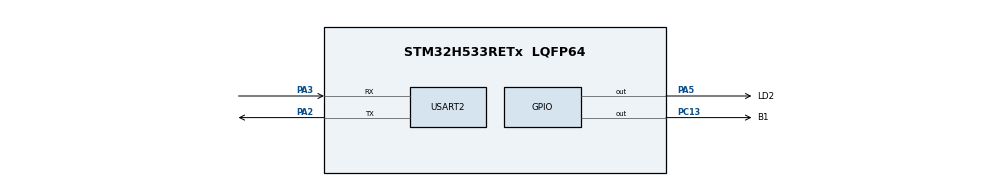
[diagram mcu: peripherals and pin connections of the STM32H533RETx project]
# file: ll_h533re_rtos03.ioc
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BOOTPATH.BootPathName=LEGACY
BOOTPATH.UserSelectedBootPath=LEGACY
CORTEX_M33_NS.userName=CORTEX_M33
Mcu.Family=STM32H5
Mcu.Name=STM32H533RETx
Mcu.Package=LQFP64
NVIC.PriorityGroup=NVIC_PRIORITYGROUP_4
PA2.Mode=Asynchronous
PA2.Signal=USART2_TX
PA3.Mode=Asynchronous
PA3.Signal=USART2_RX
PA5.GPIO_Label=LD2
PA5.Signal=GPIO_Output
PC13.GPIO_Label=B1
PC13.Signal=GPIO_Output
ProjectManager.HeapSize=0x200
ProjectManager.StackSize=0x400
ProjectManager.TargetToolchain=STM32CubeIDE
RCC.ADCFreq_Value=250000000
RCC.AHBFreq_Value=250000000
RCC.APB1Freq_Value=250000000
RCC.APB1TimFreq_Value=250000000
RCC.APB2Freq_Value=250000000
RCC.APB2TimFreq_Value=250000000
RCC.APB3Freq_Value=250000000
RCC.CSI_VALUE=4000000
RCC.CortexFreq_Value=250000000
RCC.EPOD_VALUE=4000000
RCC.HCLKFreq_Value=250000000
RCC.HSE_VALUE=25000000
RCC.HSI48_VALUE=48000000
RCC.HSI_VALUE=64000000
RCC.LSE_VALUE=32768
RCC.LSIRC_VALUE=32000
RCC.PLLN=125
RCC.SYSCLKFreq_VALUE=250000000
RCC.SYSCLKSource=RCC_SYSCLKSOURCE_PLLCLK
RCC.USBFreq_Value=48000000
RCC.VCOOutputFreq_Value=500000000
USART2.VirtualMode-Asynchronous=VM_ASYNC
VP_BOOTPATH_VS_BOOTPATH.Mode=BP_Activate
VP_CORTEX_M33_NS_VS_Hclk.Mode=Hclk_Mode
VP_MEMORYMAP_VS_MEMORYMAP.Mode=CurAppReg
VP_PWR_VS_DBSignals.Mode=DisableDeadBatterySignals
VP_PWR_VS_LPOM.Mode=PowerOptimisation
VP_PWR_VS_SECSignals.Mode=Security/Privilege
board=custom

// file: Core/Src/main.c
/* USER CODE BEGIN Header */
/**
  ******************************************************************************
  * @file           : main.c
  * @brief          : Main program body
  ******************************************************************************
  * @attention
  *
  * Copyright (c) 2024 STMicroelectronics.
  * All rights reserved.
  *
  * This software is licensed under terms that can be found in the LICENSE file
  * in the root directory of this software component.
  * If no LICENSE file comes with this software, it is provided AS-IS.
  *
  ******************************************************************************
  */
/* USER CODE END Header */
#include "main.h"

void SystemClock_Config(void);
static void MX_GPIO_Init(void);
static void MX_USART2_UART_Init(void);

int main(void)
{

  /* MCU Configuration--------------------------------------------------------*/

  /* Reset of all peripherals, Initializes the Flash interface and the Systick. */

  /* System interrupt init*/
  NVIC_SetPriorityGrouping(NVIC_PRIORITYGROUP_4);

  /* SysTick_IRQn interrupt configuration */
  NVIC_SetPriority(SysTick_IRQn, NVIC_EncodePriority(NVIC_GetPriorityGrouping(),15, 0));

  /** Disable the internal Pull-Up in Dead Battery pins of UCPD peripheral
  */
  LL_PWR_DisableUCPDDeadBattery();

  /* Configure the system clock */
  SystemClock_Config();

  /* Initialize all configured peripherals */
  MX_GPIO_Init();
  MX_USART2_UART_Init();
  /* USER CODE BEGIN 2 */
	LL_SYSTICK_EnableIT();
	main_rtos();
  /* USER CODE END 2 */

  /* Infinite loop */
	while (1) {

    /* USER CODE BEGIN 3 */
		LL_GPIO_TogglePin(LD2_GPIO_Port, LD2_Pin);
		if (LL_USART_IsActiveFlag_TXE_TXFNF(USART2)) {
			LL_USART_TransmitData8(USART2, 'u');
		}
		LL_mDelay(500);
	}
  /* USER CODE END 3 */
}

void SystemClock_Config(void)
{
  LL_FLASH_SetLatency(LL_FLASH_LATENCY_5);
  while(LL_FLASH_GetLatency()!= LL_FLASH_LATENCY_5)
  {
  }

  LL_PWR_SetRegulVoltageScaling(LL_PWR_REGU_VOLTAGE_SCALE0);
  while (LL_PWR_IsActiveFlag_VOS() == 0)
  {
  }
  LL_RCC_CSI_Enable();

   /* Wait till CSI is ready */
  while(LL_RCC_CSI_IsReady() != 1)
  {
  }

  LL_RCC_CSI_SetCalibTrimming(32);
  LL_RCC_PLL1_SetSource(LL_RCC_PLL1SOURCE_CSI);
  LL_RCC_PLL1_SetVCOInputRange(LL_RCC_PLLINPUTRANGE_4_8);
  LL_RCC_PLL1_SetVCOOutputRange(LL_RCC_PLLVCORANGE_WIDE);
  LL_RCC_PLL1_SetM(1);
  LL_RCC_PLL1_SetN(125);
  LL_RCC_PLL1_SetP(2);
  LL_RCC_PLL1_SetQ(2);
  LL_RCC_PLL1_SetR(2);
  LL_RCC_PLL1P_Enable();
  LL_RCC_PLL1_Enable();

   /* Wait till PLL is ready */
  while(LL_RCC_PLL1_IsReady() != 1)
  {
  }

  LL_RCC_SetSysClkSource(LL_RCC_SYS_CLKSOURCE_PLL1);

   /* Wait till System clock is ready */
  while(LL_RCC_GetSysClkSource() != LL_RCC_SYS_CLKSOURCE_STATUS_PLL1)
  {
  }

  LL_RCC_SetAHBPrescaler(LL_RCC_SYSCLK_DIV_1);
  LL_RCC_SetAPB1Prescaler(LL_RCC_APB1_DIV_1);
  LL_RCC_SetAPB2Prescaler(LL_RCC_APB2_DIV_1);
  LL_RCC_SetAPB3Prescaler(LL_RCC_APB3_DIV_1);

  LL_Init1msTick(250000000);

  LL_SetSystemCoreClock(250000000);
}

static void MX_USART2_UART_Init(void)
{

  LL_USART_InitTypeDef USART_InitStruct = {0};

  LL_GPIO_InitTypeDef GPIO_InitStruct = {0};

  LL_RCC_SetUSARTClockSource(LL_RCC_USART2_CLKSOURCE_PCLK1);

  /* Peripheral clock enable */
  LL_APB1_GRP1_EnableClock(LL_APB1_GRP1_PERIPH_USART2);

  LL_AHB2_GRP1_EnableClock(LL_AHB2_GRP1_PERIPH_GPIOA);
  /**USART2 GPIO Configuration
  PA2   ------> USART2_TX
  PA3   ------> USART2_RX
  */
  GPIO_InitStruct.Pin = LL_GPIO_PIN_2|LL_GPIO_PIN_3;
  GPIO_InitStruct.Mode = LL_GPIO_MODE_ALTERNATE;
  GPIO_InitStruct.Speed = LL_GPIO_SPEED_FREQ_LOW;
  GPIO_InitStruct.OutputType = LL_GPIO_OUTPUT_PUSHPULL;
  GPIO_InitStruct.Pull = LL_GPIO_PULL_NO;
  GPIO_InitStruct.Alternate = LL_GPIO_AF_7;
  LL_GPIO_Init(GPIOA, &GPIO_InitStruct);

  USART_InitStruct.PrescalerValue = LL_USART_PRESCALER_DIV1;
  USART_InitStruct.BaudRate = 115200;
  USART_InitStruct.DataWidth = LL_USART_DATAWIDTH_8B;
  USART_InitStruct.StopBits = LL_USART_STOPBITS_1;
  USART_InitStruct.Parity = LL_USART_PARITY_NONE;
  USART_InitStruct.TransferDirection = LL_USART_DIRECTION_TX_RX;
  USART_InitStruct.HardwareFlowControl = LL_USART_HWCONTROL_NONE;
  USART_InitStruct.OverSampling = LL_USART_OVERSAMPLING_16;
  LL_USART_Init(USART2, &USART_InitStruct);
  LL_USART_SetTXFIFOThreshold(USART2, LL_USART_FIFOTHRESHOLD_1_8);
  LL_USART_SetRXFIFOThreshold(USART2, LL_USART_FIFOTHRESHOLD_1_8);
  LL_USART_DisableFIFO(USART2);
  LL_USART_ConfigAsyncMode(USART2);
  LL_USART_Enable(USART2);

}

static void MX_GPIO_Init(void)
{
  LL_GPIO_InitTypeDef GPIO_InitStruct = {0};

  /* GPIO Ports Clock Enable */
  LL_AHB2_GRP1_EnableClock(LL_AHB2_GRP1_PERIPH_GPIOC);
  LL_AHB2_GRP1_EnableClock(LL_AHB2_GRP1_PERIPH_GPIOA);

  /**/
  LL_GPIO_ResetOutputPin(B1_GPIO_Port, B1_Pin);

  /**/
  LL_GPIO_ResetOutputPin(LD2_GPIO_Port, LD2_Pin);

  /**/
  GPIO_InitStruct.Pin = B1_Pin;
  GPIO_InitStruct.Mode = LL_GPIO_MODE_OUTPUT;
  GPIO_InitStruct.Speed = LL_GPIO_SPEED_FREQ_LOW;
  GPIO_InitStruct.OutputType = LL_GPIO_OUTPUT_PUSHPULL;
  GPIO_InitStruct.Pull = LL_GPIO_PULL_NO;
  LL_GPIO_Init(B1_GPIO_Port, &GPIO_InitStruct);

  /**/
  GPIO_InitStruct.Pin = LD2_Pin;
  GPIO_InitStruct.Mode = LL_GPIO_MODE_OUTPUT;
  GPIO_InitStruct.Speed = LL_GPIO_SPEED_FREQ_LOW;
  GPIO_InitStruct.OutputType = LL_GPIO_OUTPUT_PUSHPULL;
  GPIO_InitStruct.Pull = LL_GPIO_PULL_NO;
  LL_GPIO_Init(LD2_GPIO_Port, &GPIO_InitStruct);

}

void Error_Handler(void)
{
  __disable_irq();
  while (1)
  {
  }
}
